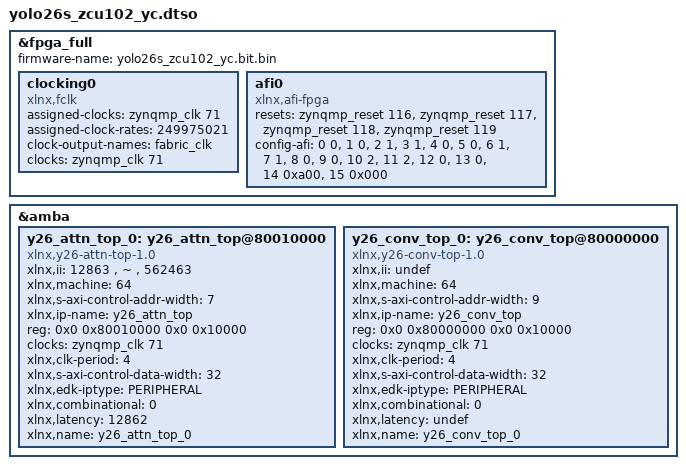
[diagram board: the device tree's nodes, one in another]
/dts-v1/;
/plugin/;
&fpga_full {
	firmware-name = "yolo26s_zcu102_yc.bit.bin";
	clocking0: clocking0 {
		compatible = "xlnx,fclk";
		assigned-clocks = <&zynqmp_clk 71>;
		assigned-clock-rates = <249975021>;
		#clock-cells = <0>;
		clock-output-names = "fabric_clk";
		clocks = <&zynqmp_clk 71>;
	};
	afi0: afi0 {
		compatible = "xlnx,afi-fpga";
		resets = <&zynqmp_reset 116>, <&zynqmp_reset 117>, <&zynqmp_reset 118>, <&zynqmp_reset 119>;
		config-afi = < 0 0>, <1 0>, <2 1>, <3 1>, <4 0>, <5 0>, <6 1>, <7 1>, <8 0>, <9 0>, <10 2>, <11 2>, <12 0>, <13 0>, <14 0xa00>, <15 0x000>;
	};
};

&amba {
	y26_attn_top_0: y26_attn_top@80010000 {
		compatible = "xlnx,y26-attn-top-1.0";
		xlnx,ii = "12863 , ~ , 562463";
		xlnx,machine = <64>;
		xlnx,s-axi-control-addr-width = <7>;
		xlnx,ip-name = "y26_attn_top";
		reg = <0x0 0x80010000 0x0 0x10000>;
		clocks = <&zynqmp_clk 71>;
		xlnx,clk-period = <4>;
		xlnx,s-axi-control-data-width = <32>;
		xlnx,edk-iptype = "PERIPHERAL";
		clock-names = "ap_clk";
		xlnx,combinational = <0>;
		xlnx,latency = <12862>;
		xlnx,name = "y26_attn_top_0";
	};
	y26_conv_top_0: y26_conv_top@80000000 {
		compatible = "xlnx,y26-conv-top-1.0";
		xlnx,ii = "undef";
		xlnx,machine = <64>;
		xlnx,s-axi-control-addr-width = <9>;
		xlnx,ip-name = "y26_conv_top";
		reg = <0x0 0x80000000 0x0 0x10000>;
		clocks = <&zynqmp_clk 71>;
		xlnx,clk-period = <4>;
		xlnx,s-axi-control-data-width = <32>;
		xlnx,edk-iptype = "PERIPHERAL";
		clock-names = "ap_clk";
		xlnx,combinational = <0>;
		xlnx,latency = "undef";
		xlnx,name = "y26_conv_top_0";
	};
};
